# SYSCTRL_PADCONF_CORE register map
Vendor: Texas Instruments
Registers are 32-bit, access per field, reset 0x10F010F unless marked. A register's access mark holds for its fields unless they carry their own. Offsets are as the file gives them; [hi:lo] are bit positions; lines under a group give offsets from that group; {n}, {i} and the like mark numbered series; 'fields as' and 'values as' point back to an identical list.

## SYSCTRL_PADCONF_CORE (part 10 of 10)
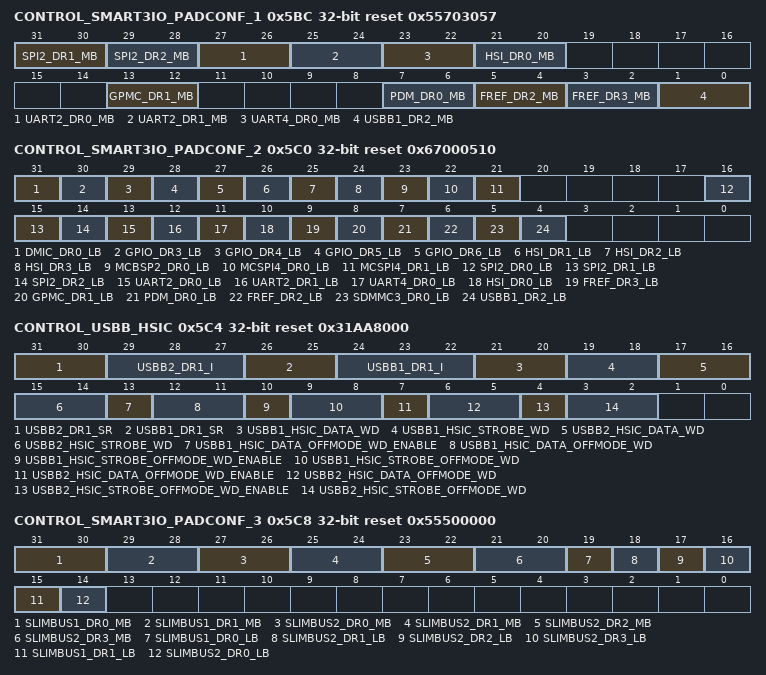
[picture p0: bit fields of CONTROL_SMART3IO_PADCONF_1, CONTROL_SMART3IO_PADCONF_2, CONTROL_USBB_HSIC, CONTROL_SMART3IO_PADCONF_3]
0x5BC CONTROL_SMART3IO_PADCONF_1 reset 0x55703057 — SMART3 I/O control 1 Access conditions. Read: unrestricted, Write: unrestricted
  [31:30] SPI2_DR1_MB rw — 50-Ω output buffer mode control for group spi2_dr1. Refer to 50-Ω output buffer I/Os with combined Mode and Load Settings for more details on mode settings.
  [29:28] SPI2_DR2_MB rw — 50-Ω output buffer mode control for group spi2_dr1. Refer to 50-Ω output buffer I/Os with combined Mode and Load Settings for more details on mode settings.
  [27:26] UART2_DR0_MB rw — 50-Ω output buffer mode control for group spi2_dr1. Refer to 50-Ω output buffer I/Os with combined Mode and Load Settings for more details on mode settings.
  [25:24] UART2_DR1_MB rw — 50-Ω output buffer mode control for group spi2_dr1. Refer to 50-Ω output buffer I/Os with combined Mode and Load Settings for more details on mode settings.
  [23:22] UART4_DR0_MB rw — 50-Ω output buffer mode control for group spi2_dr1. Refer to 50-Ω output buffer I/Os with combined Mode and Load Settings for more details on mode settings.
  [21:20] HSI_DR0_MB rw — 25-Ω output buffer mode control for group hsi_dr0. Refer to I/Os with combined Mode and Load Settings for more details on mode settings.
  [13:12] GPMC_DR1_MB rw — 50-Ω output buffer mode control for group gpmc_dr1. Refer to 50-Ω output buffer I/Os with combined Mode and Load Settings for more details on mode settings.
  [7:6] PDM_DR0_MB rw — 50-Ω output buffer mode control for group pdm_dr0. Refer to 50-Ω output buffer I/Os with combined Mode and Load Settings for more details on mode settings.
  [5:4] FREF_DR2_MB rw — 50-Ω output buffer mode control for group fref_dr2. Refer to 50-Ω output buffer I/Os with combined Mode and Load Settings for more details on mode settings.
  [3:2] FREF_DR3_MB rw — 50-Ω output buffer mode control for group fref_dr3. Refer to 50-Ω output buffer I/Os with combined Mode and Load Settings for more details on mode settings.
  [1:0] USBB1_DR2_MB rw — 25-Ω output buffer mode control for group usbb1_dr2. Refer to I/Os with combined Mode and Load Settings for more details on mode settings.
0x5C0 CONTROL_SMART3IO_PADCONF_2 reset 0x67000510 — SMART3 I/O control 2 Access conditions. Read: unrestricted, Write: unrestricted
  [31] DMIC_DR0_LB rw — 50-Ω output buffer load control dmic_dr0_lb Refer to 50-Ω output buffer I/Os with combined Mode and Load Settings for more details on mode settings.
  [30] GPIO_DR3_LB rw — 25-Ω output buffer load control gpio_dr3_lb Refer to I/Os with combined Mode and Load Settings for more details on mode settings.
  [29] GPIO_DR4_LB rw — 25-Ω output buffer load control gpio_dr4_lb Refer to I/Os with combined Mode and Load Settings for more details on mode settings.
  [28] GPIO_DR5_LB rw — 50-Ω output buffer load control gpio_dr5_lb Refer to 50-Ω output buffer I/Os with combined Mode and Load Settings for more details on mode settings.
  [27] GPIO_DR6_LB rw — 50-Ω output buffer load control gpio_dr6_lb Refer to 50-Ω output buffer I/Os with combined Mode and Load Settings for more details on mode settings.
  [26] HSI_DR1_LB rw — 25-Ω output buffer load control hsi_dr1_lb Refer to I/Os with combined Mode and Load Settings for more details on mode settings.
  [25] HSI_DR2_LB rw — 25-Ω output buffer load control hsi_dr2_lb Refer to I/Os with combined Mode and Load Settings for more details on mode settings.
  [24] HSI_DR3_LB rw — 25-Ω output buffer load control hsi_dr3_lb Refer to I/Os with combined Mode and Load Settings for more details on mode settings.
  [23] MCBSP2_DR0_LB rw — 50-Ω output buffer load control mcbsp2_dr0_lb Refer to 50-Ω output buffer I/Os with combined Mode and Load Settings for more details on mode settings.
  [22] MCSPI4_DR0_LB rw — 50-Ω output buffer load control mcspi4_dr0_lb Refer to 50-Ω output buffer I/Os with combined Mode and Load Settings for more details on mode settings.
  [21] MCSPI4_DR1_LB rw — 50-Ω output buffer load control mcspi4_dr1_lb Refer to 50-Ω output buffer I/Os with combined Mode and Load Settings for more details on mode settings.
  [16] SPI2_DR0_LB rw — 50-Ω output buffer load control spi2_dr0_lb Refer to 50-Ω output buffer I/Os with combined Mode and Load Settings for more details on mode settings.
  [15] SPI2_DR1_LB rw — 50-Ω output buffer load control spi2_dr1_lb Refer to 50-Ω output buffer I/Os with combined Mode and Load Settings for more details on mode settings.
  [14] SPI2_DR2_LB rw — 50-Ω output buffer load control spi2_dr2_lb Refer to 50-Ω output buffer I/Os with combined Mode and Load Settings for more details on mode settings.
  [13] UART2_DR0_LB rw — 50-Ω output buffer load control uart2_dr0_lb Refer to 50-Ω output buffer I/Os with combined Mode and Load Settings for more details on mode settings.
  [12] UART2_DR1_LB rw — 50-Ω output buffer load control uart2_dr1_lb Refer to 50-Ω output buffer I/Os with combined Mode and Load Settings for more details on mode settings.
  [11] UART4_DR0_LB rw — 50-Ω output buffer load control uart4_dr0_lb Refer to 50-Ω output buffer I/Os with combined Mode and Load Settings for more details on mode settings.
  [10] HSI_DR0_LB rw — 25-Ω output buffer load control hsi_dr0 Refer to I/Os with combined Mode and Load Settings for more details on mode settings.
  [9] FREF_DR3_LB rw — 50-Ω output buffer load control fref_dr3 Refer to 50-Ω output buffer I/Os with combined Mode and Load Settings for more details on mode settings.
  [8] GPMC_DR1_LB rw — 50-Ω output buffer load control gpmc_dr1 Refer to 50-Ω output buffer I/Os with combined Mode and Load Settings for more details on mode settings.
  [7] PDM_DR0_LB rw — 50-Ω output buffer load control pdm_dr0 Refer to 50-Ω output buffer I/Os with combined Mode and Load Settings for more details on mode settings.
  [6] FREF_DR2_LB rw — 50-Ω output buffer load control fref_dr2 Refer to 50-Ω output buffer I/Os with combined Mode and Load Settings for more details on mode settings.
  [5] SDMMC3_DR0_LB rw — 50-Ω output buffer load control sdmmc3_dr0 Refer to 50-Ω output buffer I/Os with combined Mode and Load Settings for more details on mode settings.
  [4] USBB1_DR2_LB rw — 25-Ω output buffer load control usbb1_dr2 Refer to I/Os with combined Mode and Load Settings for more details on mode settings.
0x5C4 CONTROL_USBB_HSIC reset 0x31AA8000 — USBB HSIC control Access conditions. Read: unrestricted, Write: unrestricted
  [31:30] USBB2_DR1_SR rw — usbb2 Slew Rate control sr1:sr0
    0=Turn_on time 125ps for Drv8; 1=Turn_on time 500ps for Drv8; 2=Turn_on time 325ps for Drv8; 3=Turn_on time 750ps for Drv8
  [29:27] USBB2_DR1_I rw — usbb2 Impedence control i2:i0
    {v}=for Drv{v+5} (v=0..6); 7=Drv12
  [26:25] USBB1_DR1_SR rw — usbb1 Slew Rate control sr1:sr0
    values as USBB2_DR1_SR
  [24:22] USBB1_DR1_I rw — usbb1 Impedence control i2:i0
    {v}=for Drv{v+5} (v=0..6); 7=Drv12
  [21:20] USBB1_HSIC_DATA_WD rw — usbb1_hsic_data wd1:wd0
    0=Pull logic disabled; 1=pull up; 2=pull down; 3=Maintain the previous output value
  [19:18] USBB1_HSIC_STROBE_WD rw — usbb1_hsic_strobe wd1:wd0
    values as USBB1_HSIC_DATA_WD
  [17:16] USBB2_HSIC_DATA_WD rw — usbb2_hsic_data wd1:wd0
    values as USBB1_HSIC_DATA_WD
  [15:14] USBB2_HSIC_STROBE_WD rw — usbb2_hsic_strobe wd1:wd0
    values as USBB1_HSIC_DATA_WD
  [13] USBB1_HSIC_DATA_OFFMODE_WD_ENABLE rw
    0=offmode_wd1; 1=offmode_wd1
  [12:11] USBB1_HSIC_DATA_OFFMODE_WD rw — usbb1_hsic_data_offmode_wd1:wd0
    values as USBB1_HSIC_DATA_WD
  [10] USBB1_HSIC_STROBE_OFFMODE_WD_ENABLE rw
    0=offmode_wd1; 1=offmode_wd1
  [9:8] USBB1_HSIC_STROBE_OFFMODE_WD rw — usbb1_hsic_strobe_offmode_wd1:wd0
    values as USBB1_HSIC_DATA_WD
  [7] USBB2_HSIC_DATA_OFFMODE_WD_ENABLE rw
    0=offmode_wd1; 1=offmode_wd1
  [6:5] USBB2_HSIC_DATA_OFFMODE_WD rw — usbb2_hsic_data_offmode_wd1:wd0
    values as USBB1_HSIC_DATA_WD
  [4] USBB2_HSIC_STROBE_OFFMODE_WD_ENABLE rw
    0=offmode_wd1; 1=offmode_wd1
  [3:2] USBB2_HSIC_STROBE_OFFMODE_WD rw — usbb2_hsic_strobe_offmode_wd1:wd0
    values as USBB1_HSIC_DATA_WD
0x5C8 CONTROL_SMART3IO_PADCONF_3 reset 0x55500000 — SMART3 IO control 3 Access conditions. Read: unrestricted, Write: unrestricted
  [31:30] SLIMBUS1_DR0_MB rw — 50-Ω output buffer mode control for group slimbus1_dr0 Refer to 50-Ω output buffer I/Os with combined Mode and Load Settings for more details on mode settings.
  [29:28] SLIMBUS1_DR1_MB rw — 50-Ω output buffer mode control for group slimbus1_dr1 Refer to 50-Ω output buffer I/Os with combined Mode and Load Settings for more details on mode settings.
  [27-2n:26-2n] SLIMBUS2_DR{n}_MB rw (n=0..3) — 50-Ω output buffer mode control for group slimbus2_dr{n} Refer to 50-Ω output buffer I/Os with combined Mode and Load Settings for more details on mode settings.
  [19] SLIMBUS1_DR0_LB rw — 50-Ω output buffer load control for group slimbus1_dr0 Refer to 50-Ω output buffer I/Os with combined Mode and Load Settings for more details on mode settings.
  [18] SLIMBUS2_DR1_LB rw — 50-Ω output buffer load control for group slimbus2_dr1 Refer to 50-Ω output buffer I/Os with combined Mode and Load Settings for more details on mode settings.
  [17] SLIMBUS2_DR2_LB rw — 50-Ω output buffer load control for group slimbus2_dr2 Refer to 50-Ω output buffer I/Os with combined Mode and Load Settings for more details on mode settings.
  [16] SLIMBUS2_DR3_LB rw — 50-Ω output buffer load control for group slimbus2_dr3 Refer to 50-Ω output buffer I/Os with combined Mode and Load Settings for more details on mode settings.
  [15] SLIMBUS1_DR1_LB rw — 50-Ω output buffer load control for group slimbus1_dr1 Refer to 50-Ω output buffer I/Os with combined Mode and Load Settings for more details on mode settings.
  [14] SLIMBUS2_DR0_LB rw — 50-Ω output buffer load control for group slimbus2_dr0 Refer to 50-Ω output buffer I/Os with combined Mode and Load Settings for more details on mode settings.
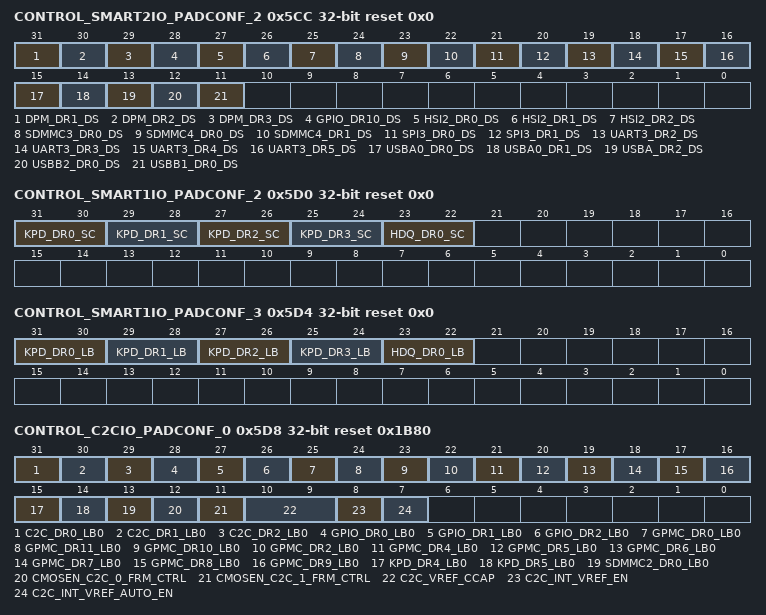
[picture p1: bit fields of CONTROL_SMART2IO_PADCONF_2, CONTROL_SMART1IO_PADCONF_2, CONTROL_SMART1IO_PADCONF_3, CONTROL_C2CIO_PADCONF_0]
0x5CC CONTROL_SMART2IO_PADCONF_2 reset 0x0 — SMART2 IO control 2 Access conditions. Read: unrestricted, Write: unrestricted
  [all] fields
    0=50 Ω; 1=25 Ω
  [31] DPM_DR1_DS rw — Drive strength control bit for group dpm_dr1
  [30] DPM_DR2_DS rw — Drive strength control bit for group dpm_dr2
  [29] DPM_DR3_DS rw — Drive strength control bit for group dpm_dr3
  [28] GPIO_DR10_DS rw — Drive strength control bit for group gpio_dr10
  [27] HSI2_DR0_DS rw — Drive strength control bit for group hsi2_dr0
  [26] HSI2_DR1_DS rw — Drive strength control bit for group hsi2_dr1
  [25] HSI2_DR2_DS rw — Drive strength control bit for group hsi2_dr2
  [24] SDMMC3_DR0_DS rw — Drive strength control bit for group sdmmc3_dr0
  [23] SDMMC4_DR0_DS rw — Drive strength control bit for group sdmmc4_dr0
  [22] SDMMC4_DR1_DS rw — Drive strength control bit for group sdmmc4_dr1
  [21] SPI3_DR0_DS rw — Drive strength control bit for group spi3_dr0
  [20] SPI3_DR1_DS rw — Drive strength control bit for group spi3_dr1
  [21-n] UART3_DR{n}_DS rw (n=2..5) — Drive strength control bit for group uart3_dr{n}
  [15] USBA0_DR0_DS rw — Drive strength control bit for group usba0_dr0
  [14] USBA0_DR1_DS rw — Drive strength control bit for group usba0_dr1
  [13] USBA_DR2_DS rw — Drive strength control bit for group usba_dr2
  [12] USBB2_DR0_DS rw — Drive strength control bit for group usbb2_dr0
  [11] USBB1_DR0_DS rw — Drive strength control bit for group usbb1_dr0
0x5D0 CONTROL_SMART1IO_PADCONF_2 reset 0x0 — SMART1 IO control 2 Access conditions. Read: unrestricted, Write: unrestricted
  [31-2n:30-2n] KPD_DR{n}_SC rw (n=0..3) — Slew rate control for group kpd_dr{n} Refer to , section Low Speed I/Os Combined Slew Rate vs TL Length and Load Settings for more details on SR settings.
  [23:22] HDQ_DR0_SC rw — Slew rate control for group hdq_dr0 Refer to , section Low Speed I/Os Combined Slew Rate vs TL Length and Load Settings for more details on SR settings.
0x5D4 CONTROL_SMART1IO_PADCONF_3 reset 0x0 — SMART1 IO control 3 Access conditions. Read: unrestricted, Write: unrestricted
  [all] fields
    0=TL Length= [2cm-20cm] / Farend cap per TL= [1pF-10pF]; 1=Dual TL Length= [20cm-40cm] / Farend cap per TL= [1pF-10pF]; 2=TL Length = [2cm-20cm] / Farend cap per TL= [10pF-20pF]; 3=Dual TL Length = [20cm-40cm] / Farend cap per TL= [10pF-20pF]
  [31-2n:30-2n] KPD_DR{n}_LB rw (n=0..3) — Load control for group kpd_dr{n}
  [23:22] HDQ_DR0_LB rw — Load control for group hdq_dr0
0x5D8 CONTROL_C2CIO_PADCONF_0 reset 0x1B80 — C2C IO control 0 Access conditions. Read: unrestricted, Write: unrestricted
  [31] C2C_DR0_LB0 rw — Mode selection bit for group c2c_dr0_LB0
    0=sdmmc2 1.2V and 1.8V / gpmc 1.2V; 1=c2c 1.2V and 1.8V / gpmc 1.8V
  [30] C2C_DR1_LB0 rw — Mode selection bit for group c2c_dr1_LB0
    values as C2C_DR0_LB0
  [29] C2C_DR2_LB0 rw — Mode selection bit for group c2c_dr2_LB0
    values as C2C_DR0_LB0
  [28] GPIO_DR0_LB0 rw — Mode selection bit for group gpio_dr0_LB0
    values as C2C_DR0_LB0
  [27] GPIO_DR1_LB0 rw — Mode selection bit for group gpio_dr1_LB0
    values as C2C_DR0_LB0
  [26] GPIO_DR2_LB0 rw — Mode selection bit for group gpio_dr2_LB0
    values as C2C_DR0_LB0
  [25] GPMC_DR0_LB0 rw — Mode selection bit for group gpmc_dr0_LB0
    values as C2C_DR0_LB0
  [24] GPMC_DR11_LB0 rw — Mode selection bit for group gpmc_dr11_LB0
    values as C2C_DR0_LB0
  [23] GPMC_DR10_LB0 rw — Mode selection bit for group gpmc_dr10_LB0
    values as C2C_DR0_LB0
  [22] GPMC_DR2_LB0 rw — Mode selection bit for group gpmc_dr2_LB0
    values as C2C_DR0_LB0
  [25-n] GPMC_DR{n}_LB0 rw (n=4..9) — Mode selection bit for group gpmc_dr{n}_LB0
    values as C2C_DR0_LB0
  [15] KPD_DR4_LB0 rw — Mode selection bit for group kpd_dr4_LB0
    values as C2C_DR0_LB0
  [14] KPD_DR5_LB0 rw — Mode selection bit for group kpd_dr5_LB0
    values as C2C_DR0_LB0
  [13] SDMMC2_DR0_LB0 rw — Mode selection bit for group sdmmc2_dr0_LB0
    values as C2C_DR0_LB0
  [12] CMOSEN_C2C_0_FRM_CTRL rw — lvcmos receiver enable in 1.2V mode for group c2c_0
    0=lvcmos rx disable; 1=lvcmos rx enable
  [11] CMOSEN_C2C_1_FRM_CTRL rw — lvcmos receiver enable in 1.2V mode for group c2c_1
    0=lvcmos rx disable; 1=lvcmos rx enable
  [10:9] C2C_VREF_CCAP rw — Selection for coupling cap connection on ivref pad
    0=No capacitor connected; 1=Capacitor between BIAS2 and VSS; 3=Capacitor between BIAS2 and VDDS as well as BIAS2 and VSS; 2=Capacitor between BIAS2 and VDDS
  [8] C2C_INT_VREF_EN rw — Internal VREF enable for C2C pads in manual mode (if both manual and auto mode is enabled then manual mode takes the priority)
    0=Disabled; 1=Enabled
  [7] C2C_INT_VREF_AUTO_EN rw — Internal VREF enable for C2C pads in auto mode (if both manual and auto mode is enabled then manual mode takes the priority)
    0=Disabled; 1=Enabled
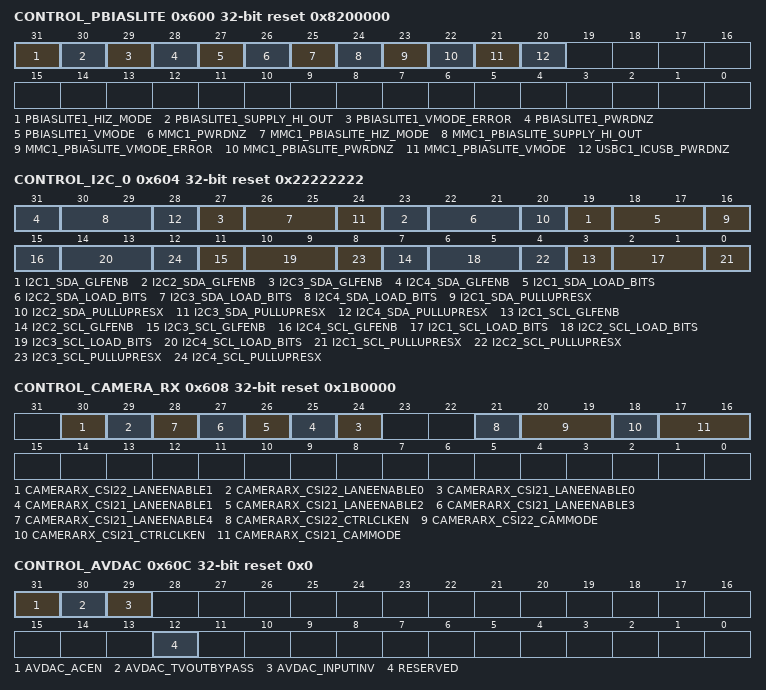
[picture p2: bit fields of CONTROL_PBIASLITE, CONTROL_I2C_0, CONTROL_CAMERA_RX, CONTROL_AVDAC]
0x600 CONTROL_PBIASLITE reset 0x8200000 — PBIASLITE control Access conditions. Read: unrestricted, Write: unrestricted
  [31] PBIASLITE1_HIZ_MODE rw — Hi-Z MODE of the PBIASLITE1
    0=PBIAS1 is in normal operation mode; 1=PBIAS1 output is in high-impedance state
  [30] PBIASLITE1_SUPPLY_HI_OUT ro — SUPPLY_HI_OUT from PBIASLITE1
    0=PBIASLITE1_SUPPLY_HI_OUT_0_r (SIM_VDDS = 1.8 V); 1=PBIASLITE1_SUPPLY_HI_OUT_1_r (SIM_VDDS = 3 V)
  [29] PBIASLITE1_VMODE_ERROR ro — VMODE ERROR from PBIASLITE1
    0=PBIASLITE1_VMODE_ERROR_0_r (VMODE level is the same as SUPPLY_HI_OUT.); 1=PBIASLITE1_VMODE_ERROR_1_r (VMODE level is not the same as SUPPLY_HI_OUT.)
  [28] PBIASLITE1_PWRDNZ rw — PWRDNZ control to PBIASLITE1. This bit is used to protect the PBIAS1 cell (associated with the gpio_wk0-gpio_wk2 pads I/O cell) when SIM_VDDS is not stable.
    0=Software must clear this bit when SIM_VDDS changes; 1=Software must set this bit only when SIM_VDDS is stable
  [27] PBIASLITE1_VMODE rw — VMODE control to PBIASLITE1
    0=SIM_VDDS = 1.8 V; 1=SIM_VDDS = 3 V
  [26] MMC1_PWRDNZ rw — PWRDNZ control to MMC1 IO. This bit is used to protect the MMC1 I/O cell when SDMMC1_VDDS is not stable.
    0=Software must clear this bit when SDMMC1_VDDS changes; 1=Software must set this bit only when SDMMC1_VDDS is stable
  [25] MMC1_PBIASLITE_HIZ_MODE rw — HIZ_MODE from MMC1 PBIASLITE
    0=PBIAS in normal operation mode; 1=PBIAS output is in high impedence state
  [24] MMC1_PBIASLITE_SUPPLY_HI_OUT ro — SUPPLY_HI_OUT from MMC1 PBIASLITE
    0=MMC1_PBIASLITE_SUPPLY_HI_OUT_0_r (SDMMC1_VDDS = 1.8V); 1=MMC1_PBIASLITE_SUPPLY_HI_OUT_1_r (SDMMC1_VDDS = 3V)
  [23] MMC1_PBIASLITE_VMODE_ERROR ro — VMODE ERROR from MMC1 PBIASLITE
    0=MMC1_PBIASLITE_VMODE_ERROR_0_r (VMODE level is same as SUPPLY_HI_OUT); 1=MMC1_PBIASLITE_VMODE_ERROR_1_r (VMODE level is not same as SUPPLY_HI_OUT)
  [22] MMC1_PBIASLITE_PWRDNZ rw — PWRDNZ control to MMC1 PBIASLITE. This bit is used to protect the MMC1_PBIAS cell (MMC1 I/O cell associated) when SDMMC1_VDDS is not stable.
    values as MMC1_PWRDNZ
  [21] MMC1_PBIASLITE_VMODE rw — VMODE control to MMC1 PBIASLITE
    0=SDMMC1_VDDS = 1.8V; 1=SDMMC1_VDDS = 3V
  [20] USBC1_ICUSB_PWRDNZ rw — PWRDNZ control to USBC1 IO. This bit is used to protect the USBC1_ICUSB I/O cell when SIM_VDDS is not stable.
    values as PBIASLITE1_PWRDNZ
0x604 CONTROL_I2C_0 rw reset 0x22222222 — I2C pads control 0 Access conditions. Read: unrestricted, Write: unrestricted
  [4n+15] I2C{n}_SDA_GLFENB (n=1..4) — Active_high glitch free operation enable pin for i2c{n} receiver
    0=Disable i2c4 glitch free operation; 1=Enable i2c4 glitch free operation
  [4n+14:4n+13] I2C{n}_SDA_LOAD_BITS (n=1..4) — Internal Pull up resistor in Fast or Standard mode /High_speed mode for i2c{n}
    0=4.5 kΩ (5-15 pF) / 1.66 kΩ (5-12 pF); 1=2.1 kΩ (15-50 pF) / 920 Ω (12-25 pF); 2=860 Ω (50-150 pF) / 500 Ω (25-50 pF); 3=N.A / 300 Ω (50-80 pF)
  [4n+12] I2C{n}_SDA_PULLUPRESX (n=1..4) — Active_low internal pull_up resistor enabled for i2c{n}
    0=Enable Internal Pull up resistor; 1=Disable Internal Pull up resisitor
  [4n-1] I2C{n}_SCL_GLFENB (n=1..4) — Active_high glitch free operation enable pin for i2c{n} receiver
    values as I2C1_SDA_GLFENB
  [4n-2:4n-3] I2C{n}_SCL_LOAD_BITS (n=1..4) — Internal Pull up resistor in Fast or Standard mode /High_speed mode for i2c{n}
    values as I2C1_SDA_LOAD_BITS
  [4n-4] I2C{n}_SCL_PULLUPRESX (n=1..4) — Active_low internal pull_up resistor enabled for i2c{n}
    values as I2C1_SDA_PULLUPRESX
0x608 CONTROL_CAMERA_RX reset 0x1B0000 — CAMERA RX control Access conditions. Read: unrestricted, Write: unrestricted
  [30] CAMERARX_CSI22_LANEENABLE1 rw — CSI22 CAMERARX lane 1 enable (CSI22_DX1, CSI22_DY1)
    0=Lane module disabled; 1=Lane module enabled
  [29] CAMERARX_CSI22_LANEENABLE0 rw — CSI22 CAMERARX lane 0 enable (CSI22_DX0, CSI22_DY0)
    0=Lane module disabled; 1=Lane module enabled
  [n+24] CAMERARX_CSI21_LANEENABLE{n} rw (n=0..4) — CSI21 CAMERARX lane {n} enable (CSI21_DX{n}, CSI21_DY{n})
    0=Lane module disabled; 1=Lane module enabled
  [21] CAMERARX_CSI22_CTRLCLKEN rw — CSI22 CAMERARX clock enable control
    0=Disable for CTRLCLK; 1=Active high enable for CTRLCLK
  [20:19] CAMERARX_CSI22_CAMMODE rw — CSI22 CAMERARX CAMMODE control
    0=DPHY mode (CSI2 mode); 1=Data/Strobe Transmission Format (CCP2 mode); 2=Data/Clock Transmission Format (CCP2/CSI1 mode)
  [18] CAMERARX_CSI21_CTRLCLKEN rw — CSI21 CAMERARX clock enable control
    0=Disable for CTRLCLK; 1=Active high enable for CTRLCLK
  [17:16] CAMERARX_CSI21_CAMMODE rw — CSI21 CAMERARX CAMMODE control
    values as CAMERARX_CSI22_CAMMODE
0x60C CONTROL_AVDAC access not given reset 0x0 — AVDAC control Access conditions. Read: unrestricted, Write: unrestricted
  [31] AVDAC_ACEN rw — AC coupling enable
    0=AC coupling disable; 1=AC coupling enable
  [30] AVDAC_TVOUTBYPASS rw — TV OUT bypass signal
    0=Video buffer is not bypassed; 1=Video buffer is bypassed
  [29] AVDAC_INPUTINV rw — Inversion control for DAC input data – din[9:0]
    0=Data inversion is disabled; 1=Data inversion is enabled
  [12] RESERVED — (access RW (Write 1 to Clear))
0x614 CONTROL_MMC2 reset 0x0 — MMC2 control Access conditions. Read: unrestricted, Write: unrestricted
  [31] MMC2_FEEDBACK_CLK_SEL rw — Feed_back clock select
    0=Clock feed_back at PAD level; 1=Clock feed_back at board level
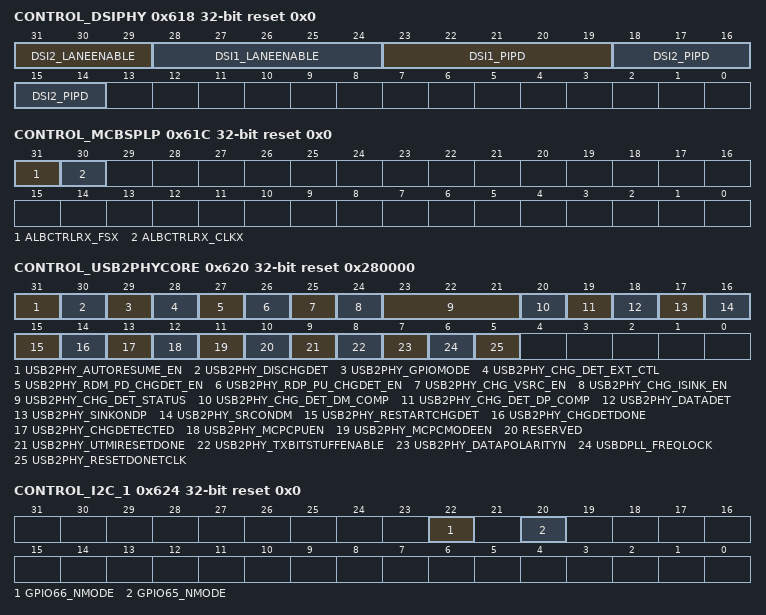
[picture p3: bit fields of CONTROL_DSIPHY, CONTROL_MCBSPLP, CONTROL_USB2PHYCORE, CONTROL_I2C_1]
0x618 CONTROL_DSIPHY reset 0x0 — DSIPHY control Access conditions. Read: unrestricted, Write: unrestricted
  [31:29] DSI2_LANEENABLE rw — DSI2 Lane EnableFor each bit, the following settings are valid: . [31] DSI2 lane 2 enable . [30] DSI2 lane 1 enable . [29] DSI2 lane 0 enable .
    0=Lane module disabled; 1=Lane module enabled
  [28:24] DSI1_LANEENABLE rw — DSI1 Lane EnableFor each bit, the following settings are valid: . [28] DSI1 lane 4 enable . [27] DSI1 lane 3 enable . [26] DSI1 lane 2 enable . [25] DSI1 lane 1 enable . [24] DSI1 lane 0 enable .
    0=Lane module disabled; 1=Lane module enabled
  [23:19] DSI1_PIPD rw — DSI1 PD EnableFor each bit, the following settings are valid: . [23] DSI1 lane 4 PD enable . [22] DSI1 lane 3 PD enable . [21] DSI1 lane 0 PD enable . [20] DSI1 lane 2 PD enable . [19] DSI1 lane 1 PD enable .
    0=Pulldown enabled; 1=Pulldown disabled
  [18:14] DSI2_PIPD rw — DSI2 PD EnableFor each bit, the following settings are valid: . [18] RESERVED (Unused) . [17] RESERVED (Unused) . [16] DSI2 lane 0 PD enable . [15] DSI2 lane 2 PD enable . [14] DSI2 lane 1 PD enable .
    0=Pulldown enabled; 1=Pulldown disabled
0x61C CONTROL_MCBSPLP reset 0x0 — McBSPLP control Access conditions. Read: unrestricted, Write: unrestricted
  [31] ALBCTRLRX_FSX rw — Analog loop_back control for FSX. This bit is programmable for only the McBSP4 instance. For the remaining three McBSP instances, this bit is hardwired to 1.
    0=PIFSR is used; 1=PIFSX is used instead of PIFSR 4pin mode
  [30] ALBCTRLRX_CLKX rw — Analog loop_back control for CLKX. This bit is programmable for only the McBSP4 instance. For the remaining three McBSP instances, this bit is hardwired to 1.
    0=PICLKR is used; 1=PICLKX is used instead of PICLKR 4pin mode
0x620 CONTROL_USB2PHYCORE reset 0x280000 — USB2PHYCORE control Access conditions. Read: unrestricted, Write: unrestricted
  [31] USB2PHY_AUTORESUME_EN rw — Auto resume enable
    0=Disable autoresume; 1=Enable autoresume
  [30] USB2PHY_DISCHGDET rw — Disable charger detect
    0=Charger detect function enabled; 1=Charger detect function disabled
  [29] USB2PHY_GPIOMODE rw — GPIO mode
    0=USB mode enabled; 1=GPIO mode enabled
  [28] USB2PHY_CHG_DET_EXT_CTL rw — Charge detect external control
    0=Charger detect internal state-machine used; 1=Charge detect state-machine is bypassed
  [27] USB2PHY_RDM_PD_CHGDET_EN rw — DM Pull down control
    0=PD disabled; 1=PD enabled
  [26] USB2PHY_RDP_PU_CHGDET_EN rw — DP Pull up control
    0=PU disabled; 1=PU enabled
  [25] USB2PHY_CHG_VSRC_EN rw — VSRC enable on DP line-Host charger case
    0=Disable VSRC drive on DP; 1=Drives VSRC 600 mV on DP line
  [24] USB2PHY_CHG_ISINK_EN rw — ISINK enable on DM line-Host charger case
    0=Disable the ISINK on DM; 1=Enables the ISINK (100 A) on DM line
  [23:21] USB2PHY_CHG_DET_STATUS ro — Status of charger detection
    0=USB2PHY_CHG_DET_STATUS_0_r (Wait state); 1=USB2PHY_CHG_DET_STATUS_1_r (No contact); 2=USB2PHY_CHG_DET_STATUS_2_r (PS/2); 3=USB2PHY_CHG_DET_STATUS_3_r (Unknown error); 4=USB2PHY_CHG_DET_STATUS_4_r (Dedicated charger); 5=USB2PHY_CHG_DET_STATUS_5_r (HOST charger); 6=USB2PHY_CHG_DET_STATUS_6_r (PC); 7=USB2PHY_CHG_DET_STATUS_7_r (Interrupt)
  [20] USB2PHY_CHG_DET_DM_COMP ro — Output of the comparator on DM during the resistor host detect protocol
    0=USB2PHY_CHG_DET_DM_COMP_0_r (DM line is below 0.75V to 0.95V); 1=USB2PHY_CHG_DET_DM_COMP_1_r (DM line is above 0.75V to 0.95V)
  [19] USB2PHY_CHG_DET_DP_COMP ro — Output of the comparator on DP during the resistor host detect protocol
    0=USB2PHY_CHG_DET_DP_COMP_0_r (DP line is below 0.75V to 0.95V); 1=USB2PHY_CHG_DET_DP_COMP_1_r (DP line is above 0.75V to 0.95V)
  [18] USB2PHY_DATADET ro — Output of the charger detect comparator
    0=USB2PHY_DATADET_0_r (DM line is below 0.25V to 0.4V); 1=USB2PHY_DATADET_1_r (DM line is above 0.25V to 0.4V)
  [17] USB2PHY_SINKONDP rw — When 1 current sink is connected to DP instead of DM
    0=Default value; 1=Enables the ISINK on DP instead of DM
  [16] USB2PHY_SRCONDM rw — When 1 voltage source is connected to DP instead of DM
    0=Default value; 1=Enable the VSRC on DM instead of DP
  [15] USB2PHY_RESTARTCHGDET rw — restartchgdet = 1 for 1 msec cause the CD_START to reset
    0=Default value; 1=A high pulse of 1 msec causes the charger detect to restart on negative edge of restartchgdet
  [14] USB2PHY_CHGDETDONE ro — Status indicates that charger detection protocol is over
    0=USB2PHY_CHGDETDONE_0_r (Charger detection protocol is not over); 1=USB2PHY_CHGDETDONE_1_r (Charger detection protocol is over)
  [13] USB2PHY_CHGDETECTED ro — Output of the charger detection protocol
    0=USB2PHY_CHGDETECTED_0_r (Charger not detected); 1=USB2PHY_CHGDETECTED_1_r (Charger detected)
  [12] USB2PHY_MCPCPUEN rw — MCPC Pull up enable
    0=Disable the MCPC pull up; 1=Enable the 4.7K to10K pull up on receive line DP when datapolarityn is 0 and DM when datapolarityn is 1
  [11] USB2PHY_MCPCMODEEN rw — MCPC Mode enable
    0=Disable MCPC mode; 1=Enable MCPC mode
  [10] RESERVED ro — Read returns reset value
  [9] USB2PHY_UTMIRESETDONE ro — UTMI FSM reset status
    0=USB2PHY_UTMIRESETDONE_0_r (UTMI FSMs are in reset); 1=USB2PHY_UTMIRESETDONE_1_r (UTMI FSMs are out of reset)
  [8] USB2PHY_TXBITSTUFFENABLE rw — TX data bit stuff enable
    0=DATAOUT [7; 1=DATAOUT [7
  [7] USB2PHY_DATAPOLARITYN rw — Data polarity
    0=DP functionality is on DP and DM funcationality is on DM; 1=DP functionality is on DM and DM functionality is on DP
  [6] USBDPLL_FREQLOCK ro — Status from USB DPLL
  [5] USB2PHY_RESETDONETCLK ro — resetdonetclk status from USB2PHY
0x624 CONTROL_I2C_1 reset 0x0 — I2C pads control 1 Access conditions. Read: unrestricted, Write: unrestricted
  [22] GPIO66_NMODE rw — Active-high selection for GPIO mode
    1=Normal (GPIO) mode
  [20] GPIO65_NMODE rw — Active-high selection for GPIO mode
    1=Normal (GPIO) mode
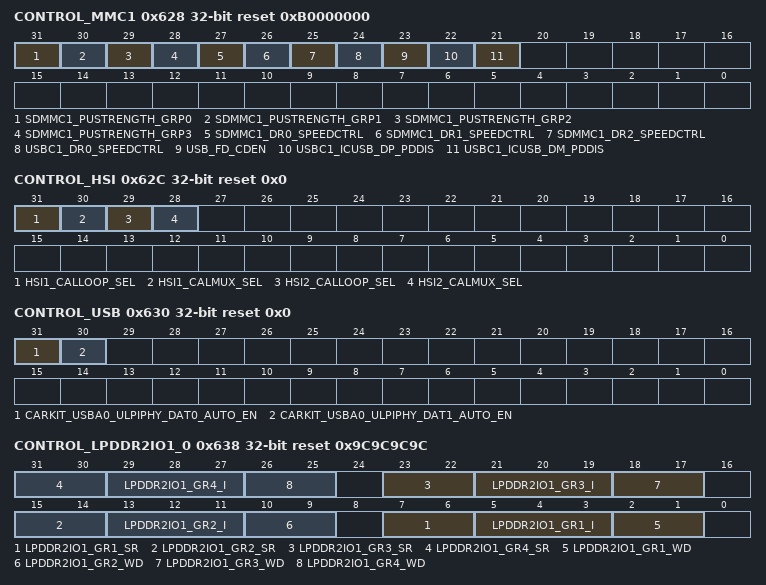
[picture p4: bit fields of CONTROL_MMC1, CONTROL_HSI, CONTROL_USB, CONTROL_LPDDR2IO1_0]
0x628 CONTROL_MMC1 reset 0xB0000000 — MMC1 control Access conditions. Read: unrestricted, Write: unrestricted
  [31-n] SDMMC1_PUSTRENGTH_GRP{n} rw (n=0..3) — Pullstrengh control for sdmmc1_pustrength_grp{n}
    0=Pull up with 50 to 110 kΩ on MMC1 data pins; 1=Pull up with 10 to 50 kΩ on MMC1 data pins
  [27] SDMMC1_DR0_SPEEDCTRL rw — Speed control for group sdmmc1_dr0
    0=FMAX = 26 MHz at 30 pF; 1=FMAX = 65 MHz at 30 pF
  [26] SDMMC1_DR1_SPEEDCTRL rw — Speed control for group sdmmc1_dr1
    0=FMAX = 26 MHz at 30 pF; 1=FMAX = 65 MHz at 30 pF
  [25] SDMMC1_DR2_SPEEDCTRL rw — Speed control for group sdmmc1_dr2
    0=FMAX = 26 MHz at 30 pF; 1=FMAX = 65 MHz at 30 pF
  [24] USBC1_DR0_SPEEDCTRL rw — Speed control for group usbc1_dr0
    0=FMAX = 26 MHz at 30 pF; 1=FMAX = 65 MHz at 30 pF
  [23] USB_FD_CDEN rw — USB FD pull down select
    0=select pull down from USB FD logic; 1=select pull down from device control modules registers
  [22] USBC1_ICUSB_DP_PDDIS rw — usbc1_icusb_dp pull down disable
    0=usbc1_icusb_dp pull down disabled; 1=usbc1_icusb_dp pull down enabled
  [21] USBC1_ICUSB_DM_PDDIS rw — usbc1_icusb_dm pull dowm disable
    0=usbc1_icusb_dm pull down disabled; 1=usbc1_icusb_dm pull down enabled
0x62C CONTROL_HSI reset 0x0 — HSI control Access conditions. Read: unrestricted, Write: unrestricted
  [all] fields
    0=Calibration mode; 1=Enable Calibration mode
  [31] HSI1_CALLOOP_SEL rw — hsi1 calibration loop select
  [30] HSI1_CALMUX_SEL rw — hsi1 calibration mux select
  [29] HSI2_CALLOOP_SEL rw — hsi2 calibration loop select
  [28] HSI2_CALMUX_SEL rw — hsi2 calibration mux select
0x630 CONTROL_USB reset 0x0 — USB control Access conditions. Read: unrestricted, Write: unrestricted
  [31] CARKIT_USBA0_ULPIPHY_DAT0_AUTO_EN rw — carkit usba0 ulpiphy dat0 auto enable
    0=Carkit Auto mode disabled; 1=Carkit Auto mode enabled
  [30] CARKIT_USBA0_ULPIPHY_DAT1_AUTO_EN rw — carkit usba0 ulpiphy dat1 auto enable
    0=Carkit Auto mode disabled; 1=Carkit Auto mode enabled
0x634 CONTROL_HDQ ro reset 0x0 — HDQ control Access conditions. Read: unrestricted, Write: unrestricted
0x638 CONTROL_LPDDR2IO1_0 reset 0x9C9C9C9C — LPDDR2 1 I/O control 0 Access conditions. Read: unrestricted, Write: unrestricted
  [8n-1:8n-2] LPDDR2IO1_GR{n}_SR rw (n=1..4) — Group {n} Slew Rate control sr1:sr0
  [8n-3:8n-5] LPDDR2IO1_GR{n}_I rw (n=1..4) — Group {n} Impedence control i2:i0
    {v}=for Drv{v+5} (v=0..6); 7=Drv12
  [8n-6:8n-7] LPDDR2IO1_GR{n}_WD rw (n=1..4) — Group {n} Weak driver control wd1:wd0
    0=Pull logic disabled; 1=Pull up; 2=Pull down; 3=Maintain the previous output value
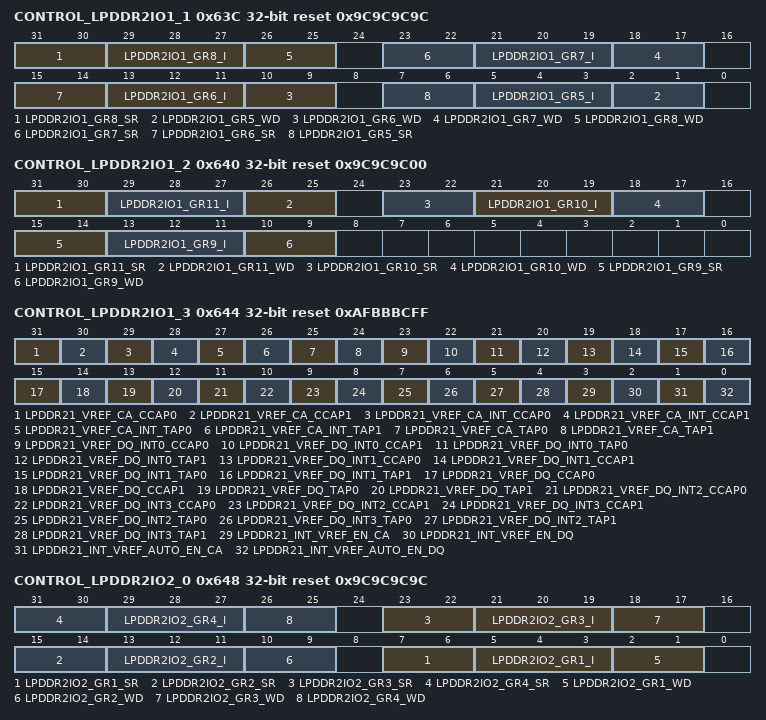
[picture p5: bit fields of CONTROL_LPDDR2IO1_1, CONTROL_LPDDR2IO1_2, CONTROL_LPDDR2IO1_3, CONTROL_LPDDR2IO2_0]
0x63C CONTROL_LPDDR2IO1_1 reset 0x9C9C9C9C — LPDDR2 1 I/O control 1 Access conditions. Read: unrestricted, Write: unrestricted
  [31:30] LPDDR2IO1_GR8_SR rw — Group 8 Slew Rate control sr1:sr0
  [8n-35:8n-37] LPDDR2IO1_GR{n}_I rw (n=5..8) — Group {n} Impedence control i2:i0
    {v}=for Drv{v+5} (v=0..6); 7=Drv12
  [8n-38:8n-39] LPDDR2IO1_GR{n}_WD rw (n=5..8) — Group {n} Weak driver control wd1:wd0
    values as CONTROL_LPDDR2IO1_0.LPDDR2IO1_GR1_WD
  [23:22] LPDDR2IO1_GR7_SR rw — Group 7 Slew Rate control sr1:sr0
  [15:14] LPDDR2IO1_GR6_SR rw — Group 6 Slew Rate control sr1:sr0
  [7:6] LPDDR2IO1_GR5_SR rw — Group 5 Slew Rate control sr1:sr0
    3=Turn_on time 390 ps for Drv8
0x640 CONTROL_LPDDR2IO1_2 reset 0x9C9C9C00 — LPDDR2 1 I/O control 2 Access conditions. Read: unrestricted, Write: unrestricted
  [31:30] LPDDR2IO1_GR11_SR rw — Group 11 Slew Rate control sr1:sr0
  [29:27] LPDDR2IO1_GR11_I rw — Group 11 Impedence control i2:i0
    {v}=for Drv{v+5} (v=0..6); 7=Drv12
  [26:25] LPDDR2IO1_GR11_WD rw — Group 11 Weak driver control wd1:wd0
    values as CONTROL_LPDDR2IO1_0.LPDDR2IO1_GR1_WD
  [23:22] LPDDR2IO1_GR10_SR rw — Group 10 Slew Rate control sr1:sr0
  [21:19] LPDDR2IO1_GR10_I rw — Group 10 Impedence control i2:i0
    {v}=for Drv{v+5} (v=0..6); 7=Drv12
  [18:17] LPDDR2IO1_GR10_WD rw — Group 10 Weak driver control wd1:wd0
    values as CONTROL_LPDDR2IO1_0.LPDDR2IO1_GR1_WD
  [15:14] LPDDR2IO1_GR9_SR rw — Group 9 Slew Rate control sr1:sr0
  [13:11] LPDDR2IO1_GR9_I rw — Group 9 Impedence control i2:i0
    {v}=for Drv{v+5} (v=0..6); 7=Drv12
  [10:9] LPDDR2IO1_GR9_WD rw — Group 9 Weak driver control wd1:wd0
    values as CONTROL_LPDDR2IO1_0.LPDDR2IO1_GR1_WD
0x644 CONTROL_LPDDR2IO1_3 rw reset 0xAFBBBCFF — LPDDR2 1 I/O control 3 Access conditions. Read: unrestricted, Write: unrestricted
  [all] fields
    0=Disabled; 1=Enabled
  [31] LPDDR21_VREF_CA_CCAP0 — Selection for coupling cap connection
  [30] LPDDR21_VREF_CA_CCAP1 — Selection for coupling cap connection
  [29] LPDDR21_VREF_CA_INT_CCAP0 — Selection for coupling cap connection
  [28] LPDDR21_VREF_CA_INT_CCAP1 — Selection for coupling cap connection
  [27] LPDDR21_VREF_CA_INT_TAP0 — Selection for internal reference voltage drive
  [26] LPDDR21_VREF_CA_INT_TAP1 — Selection for internal reference voltage drive
  [25] LPDDR21_VREF_CA_TAP0 — Selection for internal reference voltage drive
  [24] LPDDR21_VREF_CA_TAP1 — Selection for internal reference voltage drive
  [23] LPDDR21_VREF_DQ_INT0_CCAP0 — Selection for coupling cap connection
  [22] LPDDR21_VREF_DQ_INT0_CCAP1 — Selection for coupling cap connection
  [21] LPDDR21_VREF_DQ_INT0_TAP0 — Selection for internal reference voltage drive
  [20] LPDDR21_VREF_DQ_INT0_TAP1 — Selection for internal reference voltage drive
  [19] LPDDR21_VREF_DQ_INT1_CCAP0 — Selection for coupling cap connection
  [18] LPDDR21_VREF_DQ_INT1_CCAP1 — Selection for coupling cap connection
  [17] LPDDR21_VREF_DQ_INT1_TAP0 — Selection for internal reference voltage drive
  [16] LPDDR21_VREF_DQ_INT1_TAP1 — Selection for internal reference voltage drive
  [15] LPDDR21_VREF_DQ_CCAP0 — Selection for coupling cap connection
  [14] LPDDR21_VREF_DQ_CCAP1 — Selection for coupling cap connection
  [13] LPDDR21_VREF_DQ_TAP0 — Selection for internal reference voltage drive
  [12] LPDDR21_VREF_DQ_TAP1 — Selection for internal reference voltage drive
  [11] LPDDR21_VREF_DQ_INT2_CCAP0 — Selection for coupling cap connection
  [10] LPDDR21_VREF_DQ_INT3_CCAP0 — Selection for coupling cap connection
  [9] LPDDR21_VREF_DQ_INT2_CCAP1 — Selection for coupling cap connection
  [8] LPDDR21_VREF_DQ_INT3_CCAP1 — Selection for coupling cap connection
  [7] LPDDR21_VREF_DQ_INT2_TAP0 — Selection for internal reference voltage drive
  [6] LPDDR21_VREF_DQ_INT3_TAP0 — Selection for internal reference voltage drive
  [5] LPDDR21_VREF_DQ_INT2_TAP1 — Selection for internal reference voltage drive
  [4] LPDDR21_VREF_DQ_INT3_TAP1 — Selection for internal reference voltage drive
  [3] LPDDR21_INT_VREF_EN_CA — Internal vref enable for CA in manual mode (if both manual and auto mode is enabled then manual mode takes the priority)
  [2] LPDDR21_INT_VREF_EN_DQ — Internal vref enable for DQ in manual mode (if both manual and auto mode is enabled then manual mode takes the priority)
  [1] LPDDR21_INT_VREF_AUTO_EN_CA — Internal vref enable for CA in auto mode (if both manual and auto mode is enabled then manual mode takes the priority)
  [0] LPDDR21_INT_VREF_AUTO_EN_DQ — Internal vref enable for DQ in auto mode (if both manual and auto mode is enabled then manual mode takes the priority)
0x648 CONTROL_LPDDR2IO2_0 reset 0x9C9C9C9C — LPDDR2 2 I/O control 0 Access conditions. Read: unrestricted, Write: unrestricted
  [8n-1:8n-2] LPDDR2IO2_GR{n}_SR rw (n=1..4) — Group {n} Slew Rate control sr1:sr0
  [8n-3:8n-5] LPDDR2IO2_GR{n}_I rw (n=1..4) — Group {n} Impedence control i2:i0
    {v}=for Drv{v+5} (v=0..6); 7=Drv12
  [8n-6:8n-7] LPDDR2IO2_GR{n}_WD rw (n=1..4) — Group {n} Weak driver control wd1:wd0
    values as CONTROL_LPDDR2IO1_0.LPDDR2IO1_GR1_WD
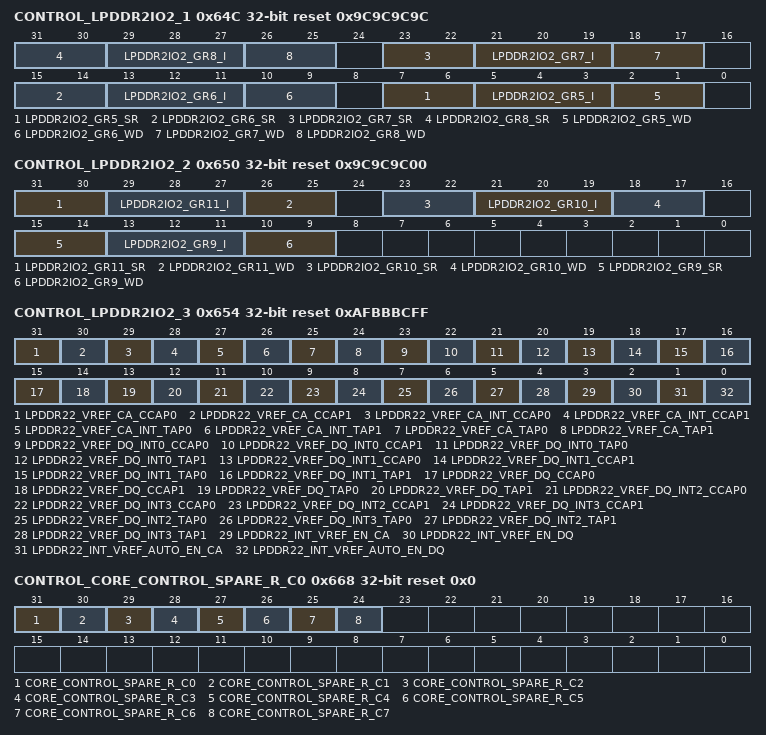
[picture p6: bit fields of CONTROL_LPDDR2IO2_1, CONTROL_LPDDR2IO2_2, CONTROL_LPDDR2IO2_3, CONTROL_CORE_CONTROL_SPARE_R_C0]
0x64C CONTROL_LPDDR2IO2_1 reset 0x9C9C9C9C — LPDDR2 2 I/O control 1 Access conditions. Read: unrestricted, Write: unrestricted
  [8n-33:8n-34] LPDDR2IO2_GR{n}_SR rw (n=5..8) — Group {n} Slew Rate control sr1:sr0
  [8n-35:8n-37] LPDDR2IO2_GR{n}_I rw (n=5..8) — Group {n} Impedence control i2:i0
    {v}=for Drv{v+5} (v=0..6); 7=Drv12
  [8n-38:8n-39] LPDDR2IO2_GR{n}_WD rw (n=5..8) — Group {n} Weak driver control wd1:wd0
    values as CONTROL_LPDDR2IO1_0.LPDDR2IO1_GR1_WD
0x650 CONTROL_LPDDR2IO2_2 reset 0x9C9C9C00 — LPDDR2 2 I/O control 2 Access conditions. Read: unrestricted, Write: unrestricted
  [31:30] LPDDR2IO2_GR11_SR rw — Group 11 Slew Rate control sr1:sr0
  [29:27] LPDDR2IO2_GR11_I rw — Group 11 Impedence control i2:i0
    {v}=for Drv{v+5} (v=0..6); 7=Drv12
  [26:25] LPDDR2IO2_GR11_WD rw — Group 11 Weak driver control wd1:wd0
    values as CONTROL_LPDDR2IO1_0.LPDDR2IO1_GR1_WD
  [23:22] LPDDR2IO2_GR10_SR rw — Group 10 Slew Rate control sr1:sr0
  [21:19] LPDDR2IO2_GR10_I rw — Group 10 Impedence control i2:i0
    {v}=for Drv{v+5} (v=0..6); 7=Drv12
  [18:17] LPDDR2IO2_GR10_WD rw — Group 10 Weak driver control wd1:wd0
    values as CONTROL_LPDDR2IO1_0.LPDDR2IO1_GR1_WD
  [15:14] LPDDR2IO2_GR9_SR rw — Group 9 Slew Rate control sr1:sr0
  [13:11] LPDDR2IO2_GR9_I rw — Group 9 Impedence control i2:i0
    {v}=for Drv{v+5} (v=0..6); 7=Drv12
  [10:9] LPDDR2IO2_GR9_WD rw — Group 9 Weak driver control wd1:wd0
    values as CONTROL_LPDDR2IO1_0.LPDDR2IO1_GR1_WD
0x654 CONTROL_LPDDR2IO2_3 rw reset 0xAFBBBCFF — LPDDR2 2 I/O control 3 Access conditions. Read: unrestricted, Write: unrestricted
  [all] fields
    0=Disabled; 1=Enabled
  [31] LPDDR22_VREF_CA_CCAP0 — Selection for coupling cap connection
  [30] LPDDR22_VREF_CA_CCAP1 — Selection for coupling cap connection
  [29] LPDDR22_VREF_CA_INT_CCAP0 — Selection for coupling cap connection
  [28] LPDDR22_VREF_CA_INT_CCAP1 — Selection for coupling cap connection
  [27] LPDDR22_VREF_CA_INT_TAP0 — Selection for internal reference voltage drive
  [26] LPDDR22_VREF_CA_INT_TAP1 — Selection for internal reference voltage drive
  [25] LPDDR22_VREF_CA_TAP0 — Selection for internal reference voltage drive
  [24] LPDDR22_VREF_CA_TAP1 — Selection for internal reference voltage drive
  [23] LPDDR22_VREF_DQ_INT0_CCAP0 — Selection for coupling cap connection
  [22] LPDDR22_VREF_DQ_INT0_CCAP1 — Selection for coupling cap connection
  [21] LPDDR22_VREF_DQ_INT0_TAP0 — Selection for internal reference voltage drive
  [20] LPDDR22_VREF_DQ_INT0_TAP1 — Selection for internal reference voltage drive
  [19] LPDDR22_VREF_DQ_INT1_CCAP0 — Selection for coupling cap connection
  [18] LPDDR22_VREF_DQ_INT1_CCAP1 — Selection for coupling cap connection
  [17] LPDDR22_VREF_DQ_INT1_TAP0 — Selection for internal reference voltage drive
  [16] LPDDR22_VREF_DQ_INT1_TAP1 — Selection for internal reference voltage drive
  [15] LPDDR22_VREF_DQ_CCAP0 — Selection for coupling cap connection
  [14] LPDDR22_VREF_DQ_CCAP1 — Selection for coupling cap connection
  [13] LPDDR22_VREF_DQ_TAP0 — Selection for internal reference voltage drive
  [12] LPDDR22_VREF_DQ_TAP1 — Selection for internal reference voltage drive
  [11] LPDDR22_VREF_DQ_INT2_CCAP0 — Selection for coupling cap connection
  [10] LPDDR22_VREF_DQ_INT3_CCAP0 — Selection for coupling cap connection
  [9] LPDDR22_VREF_DQ_INT2_CCAP1 — Selection for coupling cap connection
  [8] LPDDR22_VREF_DQ_INT3_CCAP1 — Selection for coupling cap connection
  [7] LPDDR22_VREF_DQ_INT2_TAP0 — Selection for internal reference voltage drive
  [6] LPDDR22_VREF_DQ_INT3_TAP0 — Selection for internal reference voltage drive
  [5] LPDDR22_VREF_DQ_INT2_TAP1 — Selection for internal reference voltage drive
  [4] LPDDR22_VREF_DQ_INT3_TAP1 — Selection for internal reference voltage drive
  [3] LPDDR22_INT_VREF_EN_CA — Internal vref enable for CA in manual mode (if both manual and auto mode is enabled then manual mode takes the priority)
  [2] LPDDR22_INT_VREF_EN_DQ — Internal vref enable for DQ in manual mode (if both manual and auto mode is enabled then manual mode takes the priority)
  [1] LPDDR22_INT_VREF_AUTO_EN_CA — Internal vref enable for CA in auto mode (if both manual and auto mode is enabled then manual mode takes the priority)
  [0] LPDDR22_INT_VREF_AUTO_EN_DQ — Internal vref enable for DQ in auto mode (if both manual and auto mode is enabled then manual mode takes the priority)
0x658 CONTROL_BUS_HOLD ro reset 0x0 — BUS HOLD I/O controls Access conditions. Read: unrestricted, Write: unrestricted
0x65C CONTROL_C2C rw reset 0x0 — C2C controls Access conditions. Read: unrestricted, Write: unrestricted
  [31:0] C2C_SPARE — C2C spare register bits
0x660 CONTROL_CORE_CONTROL_SPARE_RW rw reset 0x0 — CORE control spare RW Access conditions. Read: unrestricted, Write: unrestricted
  [31:0] CORE_CONTROL_SPARE_RW — Core control spare register bits RW
0x664 CONTROL_CORE_CONTROL_SPARE_R ro reset 0x0 — CORE control spare R Access conditions. Read: unrestricted, Write: unrestricted
  [31:0] CORE_CONTROL_SPARE_R — Core control spare register bits R
0x668 CONTROL_CORE_CONTROL_SPARE_R_C0 access not given reset 0x0 — CORE control spare RC Access conditions. Read: unrestricted, Write: unrestricted
  [31-n] CORE_CONTROL_SPARE_R_C{n} (n=0..7) — Core control spare register bits RC (access RW (Write 1 to Clear))
{0x668+4i} CONTROL_CORE_CONTROL_SPARE_RW{i} rw reset 0x0 (i=1..8) — CORE control spare RW{i} Access conditions. Read: unrestricted, Write: unrestricted
  [31:0] CORE_CONTROL_SPARE_RW{i} — Core control spare register bits RW{i}
0x68C CONTROL_CORE_CONTROL_SPARE_RW9 rw reset 0xFFFFFFFF — CORE control spare RW9 Access conditions. Read: unrestricted, Write: unrestricted
  [31:0] CORE_CONTROL_SPARE_RW9 — Core control spare register bits RW9
0x690 CONTROL_CORE_CONTROL_SPARE_R1 ro reset 0x0 — CORE control spare R1 Access conditions. Read: unrestricted, Write: unrestricted
  [31:0] CORE_CONTROL_SPARE_R1 — Core control spare register bits R1
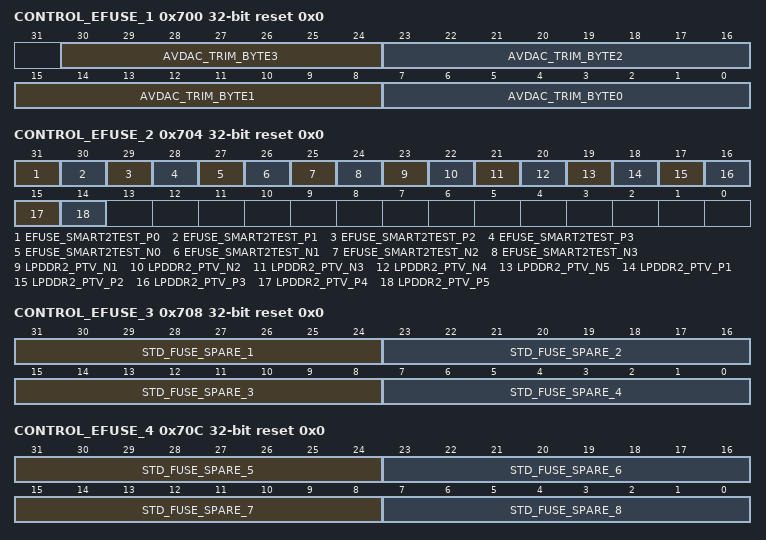
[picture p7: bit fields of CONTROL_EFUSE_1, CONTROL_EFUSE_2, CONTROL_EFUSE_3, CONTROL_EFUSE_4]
0x700 CONTROL_EFUSE_1 reset 0x0 — eFuse control 1 Access conditions. Read: unrestricted, Write: unrestricted
  [30:24] AVDAC_TRIM_BYTE3 rw — AVDAC trim byte3 (Reset value exported from eFuse) Note that reset is exported. Its value is = pi_avdac_trim_byte_3
  [23:16] AVDAC_TRIM_BYTE2 rw — AVDAC trim byte2 (Reset value exported from eFuse) Note that reset is exported. Its value is = pi_avdac_trim_byte_2
  [15:8] AVDAC_TRIM_BYTE1 rw — AVDAC trim byte1 (Reset value exported from eFuse) Note that reset is exported. Its value is = pi_avdac_trim_byte_1
  [7:0] AVDAC_TRIM_BYTE0 rw — AVDAC trim byte0 (Reset value exported from eFuse) Note that reset is exported. Its value is = pi_avdac_trim_byte_0
0x704 CONTROL_EFUSE_2 reset 0x0 — eFuse control 2 Access conditions. Read: unrestricted, Write: unrestricted
  [31-n] EFUSE_SMART2TEST_P{n} rw (n=0..3) — Smart2/3/C2C I/O PMOS process compensation bit {n} (Reset value exported from eFuse) Note that reset is exported. Its value is = pi_sr_p{n}
  [27] EFUSE_SMART2TEST_N0 rw — Smart2/3/C2C I/O NMOS process compensation bit 0 (Reset value exported from eFuse) Note that reset is exported. Its value is = pi_sr_n0
  [26] EFUSE_SMART2TEST_N1 rw — Smart2/3/C2C I/O NMOS process compensation bit 1(Reset value exported from eFuse) Note that reset is exported. Its value is = pi_sr_n1
  [25] EFUSE_SMART2TEST_N2 rw — Smart2/3/C2C I/O NMOS process compensation bit 2 (Reset value exported from eFuse) Note that reset is exported. Its value is = pi_sr_n2
  [24] EFUSE_SMART2TEST_N3 rw — Smart2/3/C2C I/O NMOS process compensation bit 3 (Reset value exported from eFuse) Note that reset is exported. Its value is = pi_sr_n3
  [24-n] LPDDR2_PTV_N{n} rw (n=1..5) — LPDDR2IO NMOS PTV code bit {n} (Reset value exported from eFuse) Note that reset is exported. Its value is = pi_lpddr2_n{n}
  [19-n] LPDDR2_PTV_P{n} rw (n=1..5) — LPDDR2IO PMOS PTV code bit {n} (Reset value exported from eFuse) Note that reset is exported. Its value is = pi_lpddr2_p{n}
0x708 CONTROL_EFUSE_3 ro reset 0x0 — eFuse control 3 Access conditions. Read: unrestricted, Write: unrestricted
  [39-8n:32-8n] STD_FUSE_SPARE_{n} (n=1..4) — std eFuse spare bits (Read Only) Note that reset is exported. Its value is = pi_std_fuse_spare{n}
0x70C CONTROL_EFUSE_4 rw reset 0x0 — eFuse control 4 Access conditions. Read: unrestricted, Write: unrestricted
  [71-8n:64-8n] STD_FUSE_SPARE_{n} (n=5..8) — std eFuse spare bits (RW) Note that reset is exported. Its value is = pi_std_fuse_spare{n}
